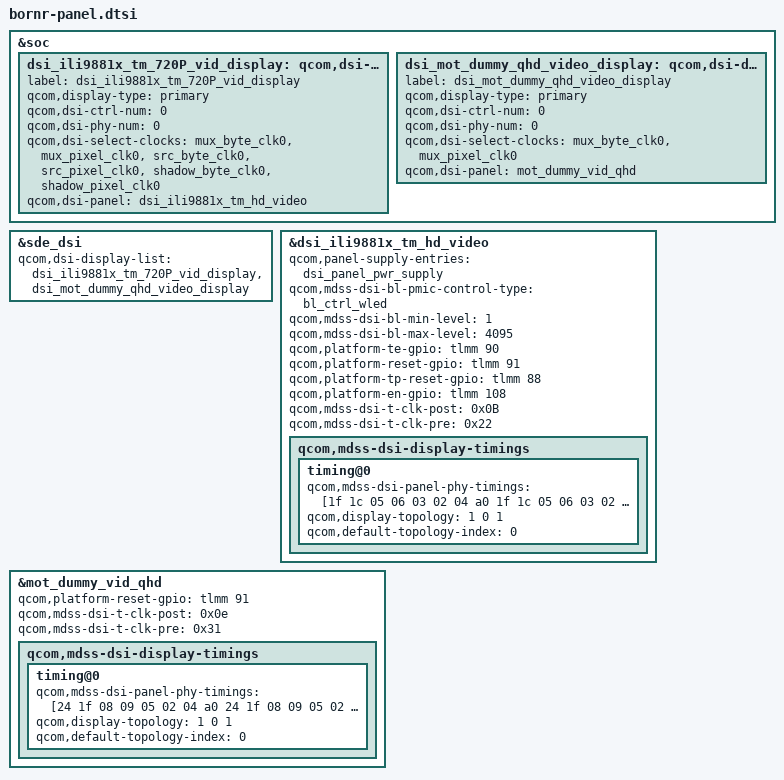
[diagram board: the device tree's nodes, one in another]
/*
 * Copyright (c) 2019, The Linux Foundation. All rights reserved.
 *
 * This program is free software; you can redistribute it and/or modify
 * it under the terms of the GNU General Public License version 2 and
 * only version 2 as published by the Free Software Foundation.
 *
 * This program is distributed in the hope that it will be useful,
 * but WITHOUT ANY WARRANTY; without even the implied warranty of
 * MERCHANTABILITY or FITNESS FOR A PARTICULAR PURPOSE.  See the
 * GNU General Public License for more details.
 */

#include "dsi-panel-mot-ili9881x-tm-720P-video.dtsi"

&soc {
	dsi_ili9881x_tm_720P_vid_display: qcom,dsi-display@10 {
		label = "dsi_ili9881x_tm_720P_vid_display";
		qcom,display-type = "primary";
		qcom,dsi-ctrl-num = <0>;
		qcom,dsi-phy-num = <0>;
		qcom,dsi-select-clocks = "mux_byte_clk0", "mux_pixel_clk0",
			"src_byte_clk0", "src_pixel_clk0",
			"shadow_byte_clk0", "shadow_pixel_clk0";
		qcom,dsi-panel = <&dsi_ili9881x_tm_hd_video>;
	};

	dsi_mot_dummy_qhd_video_display: qcom,dsi-display@11 {
		label = "dsi_mot_dummy_qhd_video_display";
		qcom,display-type = "primary";

		qcom,dsi-ctrl-num = <0>;
		qcom,dsi-phy-num = <0>;
		qcom,dsi-select-clocks = "mux_byte_clk0", "mux_pixel_clk0";

		qcom,dsi-panel = <&mot_dummy_vid_qhd>;
	};
};

&sde_dsi {
	qcom,dsi-display-list = <
				  &dsi_ili9881x_tm_720P_vid_display
                                  &dsi_mot_dummy_qhd_video_display>;
};

&dsi_ili9881x_tm_hd_video {
	qcom,panel-supply-entries = <&dsi_panel_pwr_supply>;
	qcom,mdss-dsi-bl-pmic-control-type = "bl_ctrl_wled";
	qcom,mdss-dsi-bl-min-level = <1>;
	qcom,mdss-dsi-bl-max-level = <4095>;
	qcom,platform-te-gpio = <&tlmm 90 0>;
	qcom,platform-reset-gpio = <&tlmm 91 0>;
	qcom,platform-tp-reset-gpio = <&tlmm 88 0>;
	qcom,platform-en-gpio = <&tlmm 108 0>;
	//qcom,tp-reset-enabled;

	qcom,mdss-dsi-t-clk-post = <0x0B>;
	qcom,mdss-dsi-t-clk-pre = <0x22>;
	qcom,mdss-dsi-display-timings {
		timing@0{
			qcom,mdss-dsi-panel-phy-timings =
				[1f 1c 05 06 03 02 04 a0
				1f 1c 05 06 03 02 04 a0
				1f 1c 05 06 03 02 04 a0
				1f 1c 05 06 03 02 04 a0
				1f 10 05 06 03 02 04 a0];
			qcom,display-topology = <1 0 1>;
			qcom,default-topology-index = <0>;
		};
	};
};

&mot_dummy_vid_qhd {
	//qcom,platform-te-gpio = <&tlmm 90 0>;
	qcom,platform-reset-gpio = <&tlmm 91 0>;

	qcom,mdss-dsi-t-clk-post = <0x0e>;
	qcom,mdss-dsi-t-clk-pre = <0x31>;
	qcom,mdss-dsi-display-timings {
		timing@0{
			qcom,mdss-dsi-panel-phy-timings =
				[24 1f 08 09 05 02 04 a0
				24 1f 08 09 05 02 04 a0
				24 1f 08 09 05 02 04 a0
				24 1f 08 09 05 02 04 a0
				24 1c 08 09 05 02 04 a0];

			qcom,display-topology = <1 0 1>;
			qcom,default-topology-index = <0>;
		};
	};
};
